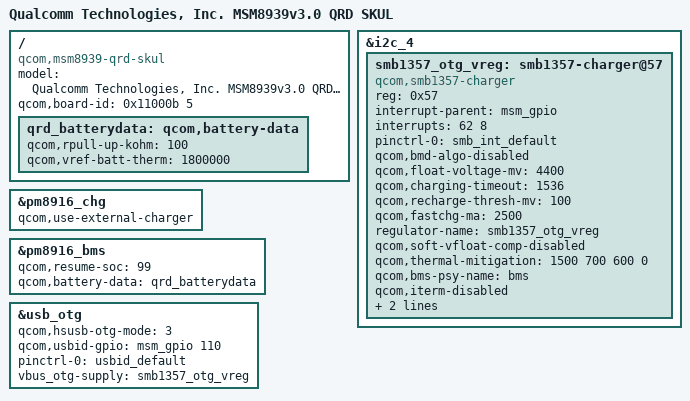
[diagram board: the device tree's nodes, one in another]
/*
 * Copyright (c) 2015, The Linux Foundation. All rights reserved.
 *
 * This program is free software; you can redistribute it and/or modify
 * it under the terms of the GNU General Public License version 2 and
 * only version 2 as published by the Free Software Foundation.
 *
 * This program is distributed in the hope that it will be useful,
 * but WITHOUT ANY WARRANTY; without even the implied warranty of
 * MERCHANTABILITY or FITNESS FOR A PARTICULAR PURPOSE.  See the
 * GNU General Public License for more details.
 */

/dts-v1/;

#include "msm8939-v3.0.dtsi"
#include "msm8939-qrd-skul.dtsi"

/ {
	model = "Qualcomm Technologies, Inc. MSM8939v3.0 QRD SKUL";
	compatible = "qcom,msm8939-qrd-skul", "qcom,msm8939-qrd", "qcom,msm8939", "qcom,qrd";
	qcom,board-id = <0x11000b 5>;
};

&i2c_4 {
	smb1357_otg_vreg: smb1357-charger@57 {
		compatible = "qcom,smb1357-charger";
		reg = <0x57>;
		interrupt-parent = <&msm_gpio>;
		interrupts = <62 8>;
		pinctrl-names = "default";
		pinctrl-0 = <&smb_int_default>;

		qcom,bmd-algo-disabled;
		qcom,float-voltage-mv = <4400>;
		qcom,charging-timeout = <1536>;
		qcom,recharge-thresh-mv = <100>;
		qcom,fastchg-ma = <2500>;
		regulator-name = "smb1357_otg_vreg";
		qcom,soft-vfloat-comp-disabled;
		qcom,thermal-mitigation = <1500 700 600 0>;

		qcom,bms-psy-name = "bms";
		qcom,iterm-disabled;
		qcom,inhibit-disabled;
		qcom,bms-controlled-charging;
	};
};

&pm8916_chg {
	status = "ok";
	qcom,use-external-charger;
};

/ {
	qrd_batterydata: qcom,battery-data {
		qcom,rpull-up-kohm = <100>;
		qcom,vref-batt-therm = <1800000>;

		#include "batterydata-qrd-skul-4v4-2920mah.dtsi"
	};
};

&pm8916_bms {
	status = "ok";
	qcom,resume-soc = <99>;
	qcom,battery-data = <&qrd_batterydata>;
};

&usb_otg {
       qcom,hsusb-otg-mode = <3>;
       qcom,usbid-gpio = <&msm_gpio 110 0>;
       pinctrl-names = "default";
       pinctrl-0 = <&usbid_default>;
       vbus_otg-supply = <&smb1357_otg_vreg>;
};
